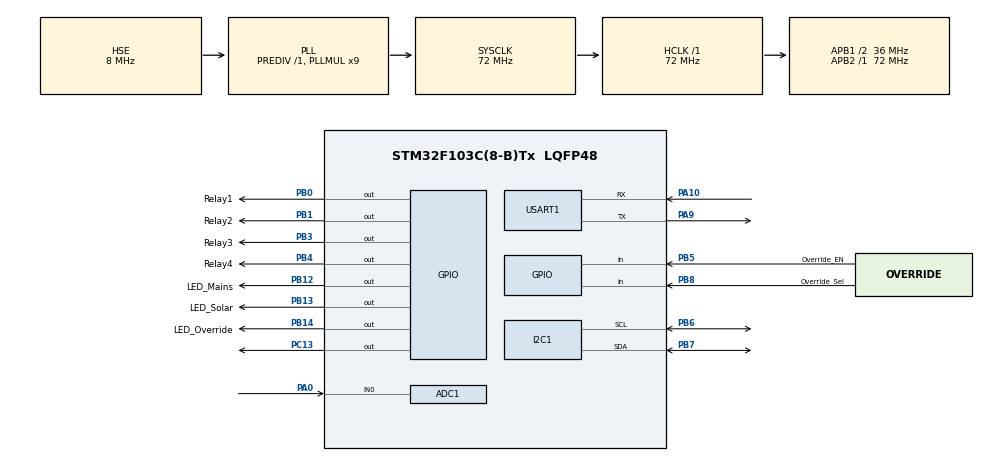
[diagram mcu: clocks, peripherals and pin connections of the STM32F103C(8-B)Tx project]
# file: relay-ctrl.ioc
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ADC1.Channel-1\#ChannelRegularConversion=ADC_CHANNEL_0
ADC1.ContinuousConvMode=ENABLE
ADC1.NbrOfConversionFlag=1
ADC1.Rank-1\#ChannelRegularConversion=1
ADC1.SamplingTime-1\#ChannelRegularConversion=ADC_SAMPLETIME_1CYCLE_5
ADC1.master=1
Dma.I2C1_RX.1.Direction=DMA_PERIPH_TO_MEMORY
Dma.I2C1_RX.1.Instance=DMA1_Channel7
Dma.I2C1_RX.1.MemDataAlignment=DMA_MDATAALIGN_BYTE
Dma.I2C1_RX.1.MemInc=DMA_MINC_ENABLE
Dma.I2C1_RX.1.Mode=DMA_NORMAL
Dma.I2C1_RX.1.PeriphDataAlignment=DMA_PDATAALIGN_BYTE
Dma.I2C1_RX.1.PeriphInc=DMA_PINC_DISABLE
Dma.I2C1_RX.1.Priority=DMA_PRIORITY_LOW
Dma.I2C1_TX.2.Direction=DMA_MEMORY_TO_PERIPH
Dma.I2C1_TX.2.Instance=DMA1_Channel6
Dma.I2C1_TX.2.MemDataAlignment=DMA_MDATAALIGN_BYTE
Dma.I2C1_TX.2.MemInc=DMA_MINC_ENABLE
Dma.I2C1_TX.2.Mode=DMA_NORMAL
Dma.I2C1_TX.2.PeriphDataAlignment=DMA_PDATAALIGN_BYTE
Dma.I2C1_TX.2.PeriphInc=DMA_PINC_DISABLE
Dma.I2C1_TX.2.Priority=DMA_PRIORITY_LOW
Dma.Request0=USART1_TX
Dma.Request1=I2C1_RX
Dma.Request2=I2C1_TX
Dma.Request3=USART1_RX
Dma.USART1_RX.3.Direction=DMA_PERIPH_TO_MEMORY
Dma.USART1_RX.3.Instance=DMA1_Channel5
Dma.USART1_RX.3.MemDataAlignment=DMA_MDATAALIGN_BYTE
Dma.USART1_RX.3.MemInc=DMA_MINC_ENABLE
Dma.USART1_RX.3.Mode=DMA_NORMAL
Dma.USART1_RX.3.PeriphDataAlignment=DMA_PDATAALIGN_BYTE
Dma.USART1_RX.3.PeriphInc=DMA_PINC_DISABLE
Dma.USART1_RX.3.Priority=DMA_PRIORITY_LOW
Dma.USART1_TX.0.Direction=DMA_MEMORY_TO_PERIPH
Dma.USART1_TX.0.Instance=DMA1_Channel4
Dma.USART1_TX.0.MemDataAlignment=DMA_MDATAALIGN_BYTE
Dma.USART1_TX.0.MemInc=DMA_MINC_ENABLE
Dma.USART1_TX.0.Mode=DMA_NORMAL
Dma.USART1_TX.0.PeriphDataAlignment=DMA_PDATAALIGN_BYTE
Dma.USART1_TX.0.PeriphInc=DMA_PINC_DISABLE
Dma.USART1_TX.0.Priority=DMA_PRIORITY_LOW
I2C1.I2C_Mode=I2C_Standard
Mcu.Family=STM32F1
Mcu.Name=STM32F103C(8-B)Tx
Mcu.Package=LQFP48
NVIC.DMA1_Channel4_IRQn=true\:0\:0\:false\:false\:true\:false\:true\:true
NVIC.DMA1_Channel5_IRQn=true\:0\:0\:false\:false\:true\:false\:true\:true
NVIC.DMA1_Channel6_IRQn=true\:0\:0\:false\:false\:true\:false\:true\:true
NVIC.DMA1_Channel7_IRQn=true\:0\:0\:false\:false\:true\:false\:true\:true
NVIC.I2C1_ER_IRQn=true\:0\:0\:false\:false\:true\:true\:true\:true
NVIC.I2C1_EV_IRQn=true\:0\:0\:false\:false\:true\:true\:true\:true
NVIC.PriorityGroup=NVIC_PRIORITYGROUP_4
NVIC.TIM2_IRQn=true\:0\:0\:false\:false\:true\:true\:true\:true
NVIC.USART1_IRQn=true\:0\:0\:false\:false\:true\:true\:true\:true
PA0-WKUP.Signal=ADCx_IN0
PA10.Mode=Asynchronous
PA10.Signal=USART1_RX
PA9.Mode=Asynchronous
PA9.Signal=USART1_TX
PB0.GPIO_Label=Relay1
PB0.GPIO_ModeDefaultOutputPP=GPIO_MODE_OUTPUT_OD
PB0.GPIO_PuPd=GPIO_PULLUP
PB0.GPIO_Speed=GPIO_SPEED_FREQ_HIGH
PB0.PinState=GPIO_PIN_SET
PB0.Signal=GPIO_Output
PB1.GPIO_Label=Relay2
PB1.GPIO_ModeDefaultOutputPP=GPIO_MODE_OUTPUT_PP
PB1.GPIO_PuPd=GPIO_PULLDOWN
PB1.PinState=GPIO_PIN_SET
PB1.Signal=GPIO_Output
PB12.GPIO_Label=LED_Mains
PB12.Signal=GPIO_Output
PB13.GPIO_Label=LED_Solar
PB13.Signal=GPIO_Output
PB14.GPIO_Label=LED_Override
PB14.Signal=GPIO_Output
PB3.GPIO_Label=Relay3
PB3.GPIO_ModeDefaultOutputPP=GPIO_MODE_OUTPUT_PP
PB3.GPIO_PuPd=GPIO_PULLDOWN
PB3.PinState=GPIO_PIN_SET
PB3.Signal=GPIO_Output
PB4.GPIO_Label=Relay4
PB4.GPIO_ModeDefaultOutputPP=GPIO_MODE_OUTPUT_PP
PB4.GPIO_PuPd=GPIO_PULLDOWN
PB4.PinState=GPIO_PIN_SET
PB4.Signal=GPIO_Output
PB5.GPIO_Label=Override_EN
PB5.Signal=GPIO_Input
PB6.Mode=I2C
PB6.Signal=I2C1_SCL
PB7.Mode=I2C
PB7.Signal=I2C1_SDA
PB8.GPIO_Label=Override_Sel
PB8.Signal=GPIO_Input
PC13-TAMPER-RTC.GPIO_Speed=GPIO_SPEED_FREQ_HIGH
PC13-TAMPER-RTC.PinState=GPIO_PIN_SET
PC13-TAMPER-RTC.Signal=GPIO_Output
PD0-OSC_IN.Mode=HSE-External-Oscillator
PD0-OSC_IN.Signal=RCC_OSC_IN
PD1-OSC_OUT.Mode=HSE-External-Oscillator
PD1-OSC_OUT.Signal=RCC_OSC_OUT
ProjectManager.HeapSize=0x200
ProjectManager.StackSize=0x400
ProjectManager.TargetToolchain=STM32CubeIDE
RCC.ADCPresc=RCC_ADCPCLK2_DIV6
RCC.AHBFreq_Value=72000000
RCC.APB1CLKDivider=RCC_HCLK_DIV2
RCC.APB1Freq_Value=36000000
RCC.APB1TimFreq_Value=72000000
RCC.APB2Freq_Value=72000000
RCC.APB2TimFreq_Value=72000000
RCC.HCLKFreq_Value=72000000
RCC.PLLMUL=RCC_PLL_MUL9
RCC.PLLSourceVirtual=RCC_PLLSOURCE_HSE
RCC.SYSCLKFreq_VALUE=72000000
RCC.SYSCLKSource=RCC_SYSCLKSOURCE_PLLCLK
RCC.USBFreq_Value=72000000
SH.ADCx_IN0.0=ADC1_IN0,IN0
TIM2.AutoReloadPreload=TIM_AUTORELOAD_PRELOAD_ENABLE
TIM2.Period=999
TIM2.Prescaler=71
TIM2.TIM_MasterOutputTrigger=TIM_TRGO_UPDATE
USART1.Parity=PARITY_EVEN
USART1.VirtualMode=VM_ASYNC
USART1.WordLength=WORDLENGTH_9B
VP_SYS_VS_ND.Mode=No_Debug
VP_TIM2_VS_ClockSourceINT.Mode=Internal
board=custom

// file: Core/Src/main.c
/* USER CODE BEGIN Header */
/**
  ******************************************************************************
  * @file           : main.c
  * @brief          : Main program body
  ******************************************************************************
  * @attention
  *
  * Copyright (c) 2025 STMicroelectronics.
  * All rights reserved.
  *
  * This software is licensed under terms that can be found in the LICENSE file
  * in the root directory of this software component.
  * If no LICENSE file comes with this software, it is provided AS-IS.
  *
  ******************************************************************************
  */
/* USER CODE END Header */
#include "main.h"

ADC_HandleTypeDef hadc1;

I2C_HandleTypeDef hi2c1;
DMA_HandleTypeDef hdma_i2c1_rx;
DMA_HandleTypeDef hdma_i2c1_tx;

TIM_HandleTypeDef htim2;

UART_HandleTypeDef huart1;
DMA_HandleTypeDef hdma_usart1_tx;
DMA_HandleTypeDef hdma_usart1_rx;

void SystemClock_Config(void);
static void MX_GPIO_Init(void);
static void MX_DMA_Init(void);
static void MX_ADC1_Init(void);
static void MX_I2C1_Init(void);
static void MX_USART1_UART_Init(void);
static void MX_TIM2_Init(void);

int main(void)
{

  /* MCU Configuration--------------------------------------------------------*/

  /* Reset of all peripherals, Initializes the Flash interface and the Systick. */
  HAL_Init();

  /* Configure the system clock */
  SystemClock_Config();

  /* Initialize all configured peripherals */
  MX_GPIO_Init();
  MX_DMA_Init();
  MX_ADC1_Init();
  MX_I2C1_Init();
  MX_USART1_UART_Init();
  MX_TIM2_Init();
  /* USER CODE BEGIN 2 */
  custom_init();
  /* USER CODE END 2 */

  /* Infinite loop */
  /* USER CODE BEGIN WHILE */
  while (1)
  {
    main_loop();
    /* USER CODE END WHILE */

  }
}

void SystemClock_Config(void)
{
  RCC_OscInitTypeDef RCC_OscInitStruct = {0};
  RCC_ClkInitTypeDef RCC_ClkInitStruct = {0};
  RCC_PeriphCLKInitTypeDef PeriphClkInit = {0};

  /** Initializes the RCC Oscillators according to the specified parameters
  * in the RCC_OscInitTypeDef structure.
  */
  RCC_OscInitStruct.OscillatorType = RCC_OSCILLATORTYPE_HSE;
  RCC_OscInitStruct.HSEState = RCC_HSE_ON;
  RCC_OscInitStruct.HSEPredivValue = RCC_HSE_PREDIV_DIV1;
  RCC_OscInitStruct.HSIState = RCC_HSI_ON;
  RCC_OscInitStruct.PLL.PLLState = RCC_PLL_ON;
  RCC_OscInitStruct.PLL.PLLSource = RCC_PLLSOURCE_HSE;
  RCC_OscInitStruct.PLL.PLLMUL = RCC_PLL_MUL9;
  if (HAL_RCC_OscConfig(&RCC_OscInitStruct) != HAL_OK)
  {
    Error_Handler();
  }

  /** Initializes the CPU, AHB and APB buses clocks
  */
  RCC_ClkInitStruct.ClockType = RCC_CLOCKTYPE_HCLK|RCC_CLOCKTYPE_SYSCLK
                              |RCC_CLOCKTYPE_PCLK1|RCC_CLOCKTYPE_PCLK2;
  RCC_ClkInitStruct.SYSCLKSource = RCC_SYSCLKSOURCE_PLLCLK;
  RCC_ClkInitStruct.AHBCLKDivider = RCC_SYSCLK_DIV1;
  RCC_ClkInitStruct.APB1CLKDivider = RCC_HCLK_DIV2;
  RCC_ClkInitStruct.APB2CLKDivider = RCC_HCLK_DIV1;

  if (HAL_RCC_ClockConfig(&RCC_ClkInitStruct, FLASH_LATENCY_2) != HAL_OK)
  {
    Error_Handler();
  }
  PeriphClkInit.PeriphClockSelection = RCC_PERIPHCLK_ADC;
  PeriphClkInit.AdcClockSelection = RCC_ADCPCLK2_DIV6;
  if (HAL_RCCEx_PeriphCLKConfig(&PeriphClkInit) != HAL_OK)
  {
    Error_Handler();
  }
}

static void MX_ADC1_Init(void)
{

  ADC_ChannelConfTypeDef sConfig = {0};

  /** Common config
  */
  hadc1.Instance = ADC1;
  hadc1.Init.ScanConvMode = ADC_SCAN_DISABLE;
  hadc1.Init.ContinuousConvMode = ENABLE;
  hadc1.Init.DiscontinuousConvMode = DISABLE;
  hadc1.Init.ExternalTrigConv = ADC_SOFTWARE_START;
  hadc1.Init.DataAlign = ADC_DATAALIGN_RIGHT;
  hadc1.Init.NbrOfConversion = 1;
  if (HAL_ADC_Init(&hadc1) != HAL_OK)
  {
    Error_Handler();
  }

  /** Configure Regular Channel
  */
  sConfig.Channel = ADC_CHANNEL_0;
  sConfig.Rank = ADC_REGULAR_RANK_1;
  sConfig.SamplingTime = ADC_SAMPLETIME_1CYCLE_5;
  if (HAL_ADC_ConfigChannel(&hadc1, &sConfig) != HAL_OK)
  {
    Error_Handler();
  }

}

static void MX_I2C1_Init(void)
{

  hi2c1.Instance = I2C1;
  hi2c1.Init.ClockSpeed = 100000;
  hi2c1.Init.DutyCycle = I2C_DUTYCYCLE_2;
  hi2c1.Init.OwnAddress1 = 0;
  hi2c1.Init.AddressingMode = I2C_ADDRESSINGMODE_7BIT;
  hi2c1.Init.DualAddressMode = I2C_DUALADDRESS_DISABLE;
  hi2c1.Init.OwnAddress2 = 0;
  hi2c1.Init.GeneralCallMode = I2C_GENERALCALL_DISABLE;
  hi2c1.Init.NoStretchMode = I2C_NOSTRETCH_DISABLE;
  if (HAL_I2C_Init(&hi2c1) != HAL_OK)
  {
    Error_Handler();
  }

}

static void MX_TIM2_Init(void)
{

  TIM_ClockConfigTypeDef sClockSourceConfig = {0};
  TIM_MasterConfigTypeDef sMasterConfig = {0};

  htim2.Instance = TIM2;
  htim2.Init.Prescaler = 71;
  htim2.Init.CounterMode = TIM_COUNTERMODE_UP;
  htim2.Init.Period = 999;
  htim2.Init.ClockDivision = TIM_CLOCKDIVISION_DIV1;
  htim2.Init.AutoReloadPreload = TIM_AUTORELOAD_PRELOAD_ENABLE;
  if (HAL_TIM_Base_Init(&htim2) != HAL_OK)
  {
    Error_Handler();
  }
  sClockSourceConfig.ClockSource = TIM_CLOCKSOURCE_INTERNAL;
  if (HAL_TIM_ConfigClockSource(&htim2, &sClockSourceConfig) != HAL_OK)
  {
    Error_Handler();
  }
  sMasterConfig.MasterOutputTrigger = TIM_TRGO_UPDATE;
  sMasterConfig.MasterSlaveMode = TIM_MASTERSLAVEMODE_DISABLE;
  if (HAL_TIMEx_MasterConfigSynchronization(&htim2, &sMasterConfig) != HAL_OK)
  {
    Error_Handler();
  }

}

static void MX_USART1_UART_Init(void)
{

  huart1.Instance = USART1;
  huart1.Init.BaudRate = 115200;
  huart1.Init.WordLength = UART_WORDLENGTH_9B;
  huart1.Init.StopBits = UART_STOPBITS_1;
  huart1.Init.Parity = UART_PARITY_EVEN;
  huart1.Init.Mode = UART_MODE_TX_RX;
  huart1.Init.HwFlowCtl = UART_HWCONTROL_NONE;
  huart1.Init.OverSampling = UART_OVERSAMPLING_16;
  if (HAL_UART_Init(&huart1) != HAL_OK)
  {
    Error_Handler();
  }

}

static void MX_DMA_Init(void)
{

  /* DMA controller clock enable */
  __HAL_RCC_DMA1_CLK_ENABLE();

  /* DMA interrupt init */
  /* DMA1_Channel4_IRQn interrupt configuration */
  HAL_NVIC_SetPriority(DMA1_Channel4_IRQn, 0, 0);
  HAL_NVIC_EnableIRQ(DMA1_Channel4_IRQn);
  /* DMA1_Channel5_IRQn interrupt configuration */
  HAL_NVIC_SetPriority(DMA1_Channel5_IRQn, 0, 0);
  HAL_NVIC_EnableIRQ(DMA1_Channel5_IRQn);
  /* DMA1_Channel6_IRQn interrupt configuration */
  HAL_NVIC_SetPriority(DMA1_Channel6_IRQn, 0, 0);
  HAL_NVIC_EnableIRQ(DMA1_Channel6_IRQn);
  /* DMA1_Channel7_IRQn interrupt configuration */
  HAL_NVIC_SetPriority(DMA1_Channel7_IRQn, 0, 0);
  HAL_NVIC_EnableIRQ(DMA1_Channel7_IRQn);

}

static void MX_GPIO_Init(void)
{
  GPIO_InitTypeDef GPIO_InitStruct = {0};

  /* GPIO Ports Clock Enable */
  __HAL_RCC_GPIOC_CLK_ENABLE();
  __HAL_RCC_GPIOD_CLK_ENABLE();
  __HAL_RCC_GPIOA_CLK_ENABLE();
  __HAL_RCC_GPIOB_CLK_ENABLE();

  /*Configure GPIO pin Output Level */
  HAL_GPIO_WritePin(GPIOC, GPIO_PIN_13, GPIO_PIN_SET);

  /*Configure GPIO pin Output Level */
  HAL_GPIO_WritePin(GPIOB, Relay1_Pin|Relay2_Pin|Relay3_Pin|Relay4_Pin, GPIO_PIN_SET);

  /*Configure GPIO pin Output Level */
  HAL_GPIO_WritePin(GPIOB, LED_Mains_Pin|LED_Solar_Pin|LED_Override_Pin, GPIO_PIN_RESET);

  /*Configure GPIO pin : PC13 */
  GPIO_InitStruct.Pin = GPIO_PIN_13;
  GPIO_InitStruct.Mode = GPIO_MODE_OUTPUT_PP;
  GPIO_InitStruct.Pull = GPIO_NOPULL;
  GPIO_InitStruct.Speed = GPIO_SPEED_FREQ_HIGH;
  HAL_GPIO_Init(GPIOC, &GPIO_InitStruct);

  /*Configure GPIO pin : Relay1_Pin */
  GPIO_InitStruct.Pin = Relay1_Pin;
  GPIO_InitStruct.Mode = GPIO_MODE_OUTPUT_OD;
  GPIO_InitStruct.Pull = GPIO_PULLUP;
  GPIO_InitStruct.Speed = GPIO_SPEED_FREQ_HIGH;
  HAL_GPIO_Init(Relay1_GPIO_Port, &GPIO_InitStruct);

  /*Configure GPIO pins : Relay2_Pin Relay3_Pin Relay4_Pin */
  GPIO_InitStruct.Pin = Relay2_Pin|Relay3_Pin|Relay4_Pin;
  GPIO_InitStruct.Mode = GPIO_MODE_OUTPUT_PP;
  GPIO_InitStruct.Pull = GPIO_PULLDOWN;
  GPIO_InitStruct.Speed = GPIO_SPEED_FREQ_LOW;
  HAL_GPIO_Init(GPIOB, &GPIO_InitStruct);

  /*Configure GPIO pins : LED_Mains_Pin LED_Solar_Pin LED_Override_Pin */
  GPIO_InitStruct.Pin = LED_Mains_Pin|LED_Solar_Pin|LED_Override_Pin;
  GPIO_InitStruct.Mode = GPIO_MODE_OUTPUT_PP;
  GPIO_InitStruct.Pull = GPIO_NOPULL;
  GPIO_InitStruct.Speed = GPIO_SPEED_FREQ_LOW;
  HAL_GPIO_Init(GPIOB, &GPIO_InitStruct);

  /*Configure GPIO pins : Override_EN_Pin Override_Sel_Pin */
  GPIO_InitStruct.Pin = Override_EN_Pin|Override_Sel_Pin;
  GPIO_InitStruct.Mode = GPIO_MODE_INPUT;
  GPIO_InitStruct.Pull = GPIO_NOPULL;
  HAL_GPIO_Init(GPIOB, &GPIO_InitStruct);

}

void Error_Handler(void)
{
  __disable_irq();
  while (1)
  {
  }
}
